# MSP432E401Y register map
Vendor: Texas Instruments; File version: 3.200
CPU: CM4 r1p2, little endian, no MPU, no FPU, 0x3 interrupt priority bits, 0x0 interrupts
Registers are 32-bit, read-write, no defined reset value unless marked. A register's access mark holds for its fields unless they carry their own. Offsets are from the block's base; [hi:lo] are bit positions; {n}, {i} and the like mark numbered series.

## WATCHDOG0 — Register map for WATCHDOG0 peripheral
Base 0x40000000; register names take the prefix WATCHDOG0
0x00 LOAD — Watchdog Load
  [31:0] WDT_LOAD — Watchdog Load Value
0x04 VALUE — Watchdog Value
  [31:0] WDT_VALUE
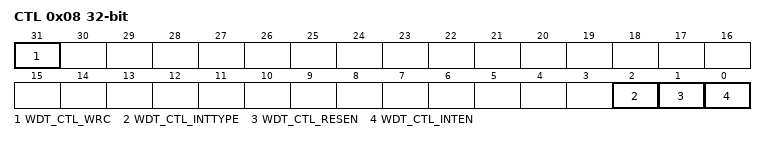
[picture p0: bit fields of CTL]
0x08 CTL — Watchdog Control
  [31] WDT_CTL_WRC — Write Complete
  [2] WDT_CTL_INTTYPE — Watchdog Interrupt Type
  [1] WDT_CTL_RESEN — Watchdog Reset Enable
  [0] WDT_CTL_INTEN — Watchdog Interrupt Enable
0x0C ICR wo — Watchdog Interrupt Clear
  [31:0] WDT_ICR
0x10 RIS — Watchdog Raw Interrupt Status
  [0] WDT_RIS_WDTRIS
0x14 MIS — Watchdog Masked Interrupt Status
  [0] WDT_MIS_WDTMIS
0x418 TEST — Watchdog Test
  [8] WDT_TEST_STALL — Watchdog Stall Enable
0xC00 LOCK — Watchdog Lock
  [31:0] WDT_LOCK
    0=WDT_LOCK_UNLOCKED (Unlocked); 1=WDT_LOCK_LOCKED (Locked)

## WATCHDOG1 — Register map for WATCHDOG0 peripheral
Base 0x40001000; register names take the prefix WATCHDOG1
Registers as WATCHDOG0.

## QEI0 — Register map for QEI0 peripheral
Base 0x4002C000; register names take the prefix QEI0
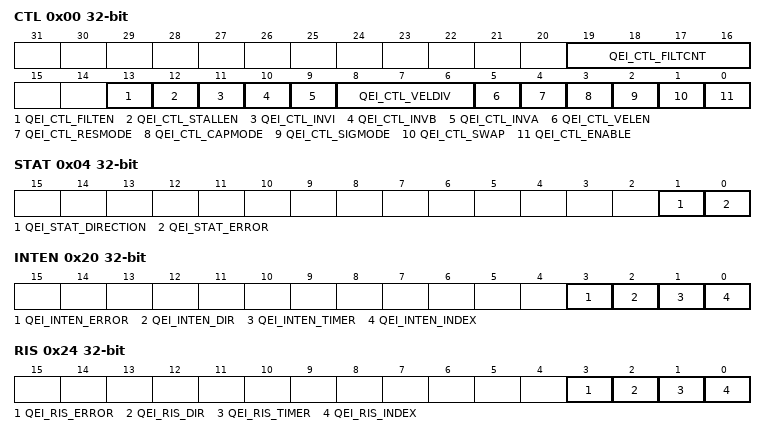
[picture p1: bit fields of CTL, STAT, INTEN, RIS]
0x00 CTL — QEI Control
  [19:16] QEI_CTL_FILTCNT — Input Filter Prescale Count
  [13] QEI_CTL_FILTEN — Enable Input Filter
  [12] QEI_CTL_STALLEN — Stall QEI
  [11] QEI_CTL_INVI — Invert Index Pulse
  [10] QEI_CTL_INVB — Invert PhB
  [9] QEI_CTL_INVA — Invert PhA
  [8:6] QEI_CTL_VELDIV — Predivide Velocity
    0=QEI clock /1; 1=QEI clock /2; 2=QEI clock /4; 3=QEI clock /8; 4=QEI clock /16; 5=QEI clock /32; 6=QEI clock /64; 7=QEI clock /128
  [5] QEI_CTL_VELEN — Capture Velocity
  [4] QEI_CTL_RESMODE — Reset Mode
  [3] QEI_CTL_CAPMODE — Capture Mode
  [2] QEI_CTL_SIGMODE — Signal Mode
  [1] QEI_CTL_SWAP — Swap Signals
  [0] QEI_CTL_ENABLE — Enable QEI
0x04 STAT — QEI Status
  [1] QEI_STAT_DIRECTION — Direction of Rotation
  [0] QEI_STAT_ERROR — Error Detected
0x08 POS — QEI Position
  [31:0] QEI_POS — Current Position Integrator Value
0x0C MAXPOS — QEI Maximum Position
  [31:0] QEI_MAXPOS — Maximum Position Integrator Value
0x10 LOAD — QEI Timer Load
  [31:0] QEI_LOAD — Velocity Timer Load Value
0x14 TIME — QEI Timer
  [31:0] QEI_TIME — Velocity Timer Current Value
0x18 COUNT — QEI Velocity Counter
  [31:0] QEI_COUNT — Velocity Pulse Count
0x1C SPEED — QEI Velocity
  [31:0] QEI_SPEED — Velocity
0x20 INTEN — QEI Interrupt Enable
  [3] QEI_INTEN_ERROR — Phase Error Interrupt Enable
  [2] QEI_INTEN_DIR — Direction Change Interrupt Enable
  [1] QEI_INTEN_TIMER — Timer Expires Interrupt Enable
  [0] QEI_INTEN_INDEX — Index Pulse Detected Interrupt Enable
0x24 RIS — QEI Raw Interrupt Status
  [3] QEI_RIS_ERROR — Phase Error Detected
  [2] QEI_RIS_DIR — Direction Change Detected
  [1] QEI_RIS_TIMER — Velocity Timer Expired
  [0] QEI_RIS_INDEX — Index Pulse Asserted
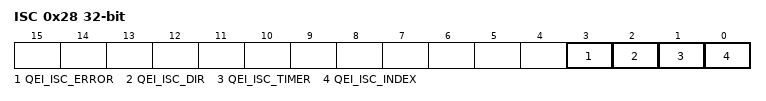
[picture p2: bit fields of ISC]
0x28 ISC — QEI Interrupt Status and Clear
  [3] QEI_ISC_ERROR — Phase Error Interrupt
  [2] QEI_ISC_DIR — Direction Change Interrupt
  [1] QEI_ISC_TIMER — Velocity Timer Expired Interrupt
  [0] QEI_ISC_INDEX — Index Pulse Interrupt

## COMP — Register map for COMP peripheral
Base 0x4003C000; register names take the prefix COMP
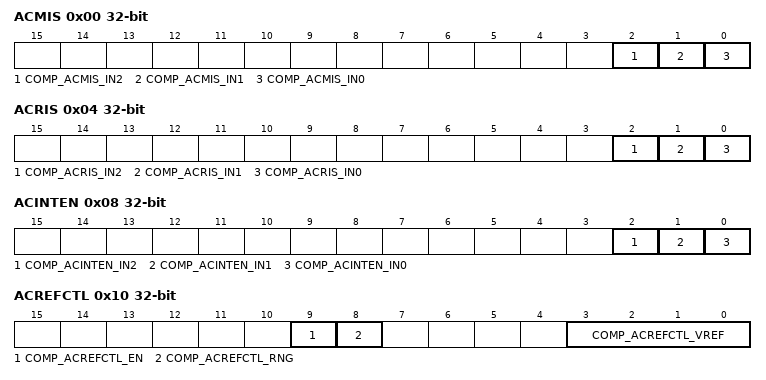
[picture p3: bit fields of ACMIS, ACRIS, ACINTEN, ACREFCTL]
0x00 ACMIS — Analog Comparator Masked Interrupt Status
  [2] COMP_ACMIS_IN2 — Comparator 2 Masked Interrupt Status
  [1] COMP_ACMIS_IN1 — Comparator 1 Masked Interrupt Status
  [0] COMP_ACMIS_IN0 — Comparator 0 Masked Interrupt Status
0x04 ACRIS — Analog Comparator Raw Interrupt Status
  [2] COMP_ACRIS_IN2 — Comparator 2 Interrupt Status
  [1] COMP_ACRIS_IN1 — Comparator 1 Interrupt Status
  [0] COMP_ACRIS_IN0 — Comparator 0 Interrupt Status
0x08 ACINTEN — Analog Comparator Interrupt Enable
  [2] COMP_ACINTEN_IN2 — Comparator 2 Interrupt Enable
  [1] COMP_ACINTEN_IN1 — Comparator 1 Interrupt Enable
  [0] COMP_ACINTEN_IN0 — Comparator 0 Interrupt Enable
0x10 ACREFCTL — Analog Comparator Reference Voltage Control
  [9] COMP_ACREFCTL_EN — Resistor Ladder Enable
  [8] COMP_ACREFCTL_RNG — Resistor Ladder Range
  [3:0] COMP_ACREFCTL_VREF — Resistor Ladder Voltage Ref
{0x20+0x20*i} ACSTAT{i} (i=0..2) — Analog Comparator Status {i}
  [1] COMP_ACSTAT{i}_OVAL — Comparator Output Value
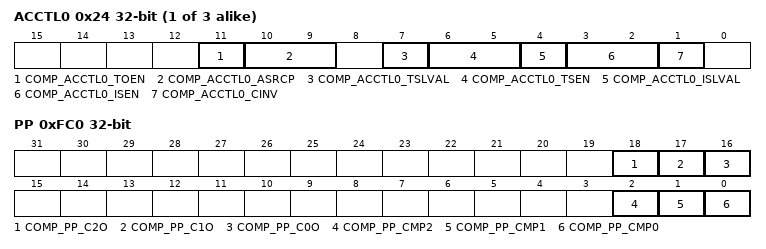
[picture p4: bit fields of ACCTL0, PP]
{0x24+0x20*i} ACCTL{i} (i=0..2) — Analog Comparator Control {i}
  [11] COMP_ACCTL{i}_TOEN — Trigger Output Enable
  [10:9] COMP_ACCTL{i}_ASRCP — Analog Source Positive
    0=COMP_ACCTL{i}_ASRCP_PIN (Pin value of Cn+); 1=COMP_ACCTL{i}_ASRCP_PIN0 (Pin value of C0+); 2=COMP_ACCTL{i}_ASRCP_REF (Internal voltage reference)
  [7] COMP_ACCTL{i}_TSLVAL — Trigger Sense Level Value
  [6:5] COMP_ACCTL{i}_TSEN — Trigger Sense
    0=COMP_ACCTL{i}_TSEN_LEVEL (Level sense, see TSLVAL); 1=COMP_ACCTL{i}_TSEN_FALL (Falling edge); 2=COMP_ACCTL{i}_TSEN_RISE (Rising edge); 3=COMP_ACCTL{i}_TSEN_BOTH (Either edge)
  [4] COMP_ACCTL{i}_ISLVAL — Interrupt Sense Level Value
  [3:2] COMP_ACCTL{i}_ISEN — Interrupt Sense
    0=COMP_ACCTL{i}_ISEN_LEVEL (Level sense, see ISLVAL); 1=COMP_ACCTL{i}_ISEN_FALL (Falling edge); 2=COMP_ACCTL{i}_ISEN_RISE (Rising edge); 3=COMP_ACCTL{i}_ISEN_BOTH (Either edge)
  [1] COMP_ACCTL{i}_CINV — Comparator Output Invert
0xFC0 PP — Analog Comparator Peripheral Properties
  [18] COMP_PP_C2O — Comparator Output 2 Present
  [17] COMP_PP_C1O — Comparator Output 1 Present
  [16] COMP_PP_C0O — Comparator Output 0 Present
  [2] COMP_PP_CMP2 — Comparator 2 Present
  [1] COMP_PP_CMP1 — Comparator 1 Present
  [0] COMP_PP_CMP0 — Comparator 0 Present
